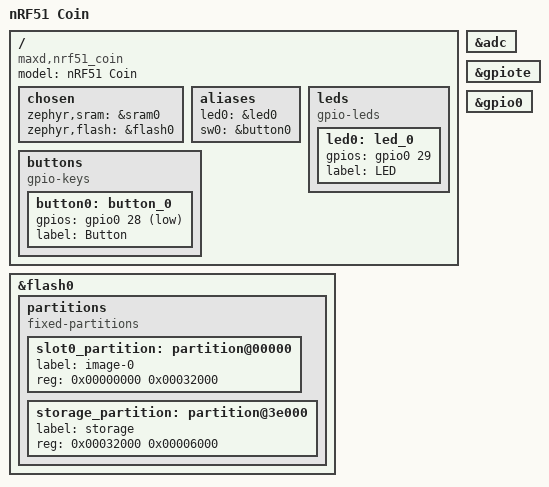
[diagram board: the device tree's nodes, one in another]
/*
 * Copyright (c) Maximilian Deubel
 *
 * SPDX-License-Identifier: Apache-2.0
 */

/dts-v1/;
#include <nordic/nrf51822_qfaa.dtsi>

/ {
	model = "nRF51 Coin";
	compatible = "maxd,nrf51_coin", "nordic,nrf51822-qfaa",
		     "nordic,nrf51822";

	chosen {
		zephyr,sram = &sram0;
		zephyr,flash = &flash0;
	};

	aliases {
		led0 = &led0;
		sw0 = &button0;
	};

	leds {
		compatible = "gpio-leds";
		led0: led_0 {
			gpios = <&gpio0 29 0>;
			label = "LED";
		};
	};

	buttons {
		compatible = "gpio-keys";
		button0: button_0 {
			gpios = <&gpio0 28 (GPIO_PUD_PULL_UP |
					    GPIO_INT_ACTIVE_LOW)>;
			label = "Button";
		};
	};
};

&adc {
	status ="okay";
};

&gpiote {
	status ="okay";
};

&gpio0 {
	status ="okay";
};

&flash0 {
	/*
	 * For more information, see:
	 * http://docs.zephyrproject.org/latest/guides/dts/index.html#flash-partitions
	 */
	partitions {
		compatible = "fixed-partitions";
		#address-cells = <1>;
		#size-cells = <1>;

		slot0_partition: partition@00000 {
			label = "image-0";
			reg = <0x00000000 0x00032000>;
		};
		storage_partition: partition@3e000 {
			label = "storage";
			reg = <0x00032000 0x00006000>;
		};
		/*
		 * REMEMBER TO UPDATE ADDRESS AND LENGTH IN prod/gen_bond.py
		 */
	};
};
